# STM32U59x register map
File version: 0.2
Registers are 32-bit, read-write, reset 0x0 unless marked. A register's access mark holds for its fields unless they carry their own. Offsets are from the block's base; [hi:lo] are bit positions; {n}, {i} and the like mark numbered series.

## RCC (part 1 of 2) — Reset and clock control
Base 0x46020C00
Same registers: SEC_RCC 0x56020C00
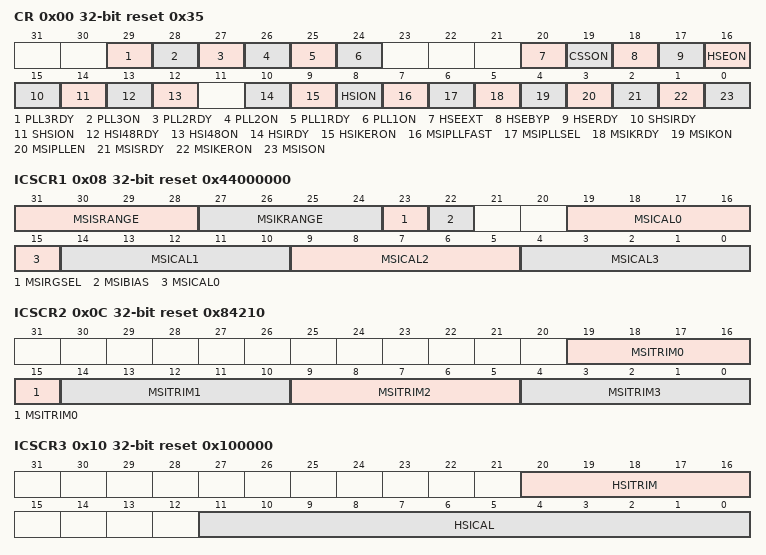
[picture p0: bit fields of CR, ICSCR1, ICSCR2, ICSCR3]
0x00 CR access per field reset 0x35 — Clock control register
  [29] PLL3RDY ro — PLL3 clock ready flag
  [28] PLL3ON rw — PLL3 enable
  [27] PLL2RDY ro — PLL2 clock ready flag
  [26] PLL2ON rw — PLL2 enable
  [25] PLL1RDY ro — PLL1 clock ready flag
  [24] PLL1ON rw — PLL1 enable
  [20] HSEEXT rw — SRAM3 page 5 (64 Kbytes) power-down in Stop modes
  [19] CSSON rw — Clock security system enable
  [18] HSEBYP rw — HSE crystal oscillator bypass
  [17] HSERDY ro — HSE clock ready flag
  [16] HSEON rw — HSE clock enable
  [15] SHSIRDY ro — SHSI clock ready flag
  [14] SHSION rw — SHSI clock enable
  [13] HSI48RDY ro — HSI48 clock ready flag
  [12] HSI48ON rw — HSI48 clock enable
  [10] HSIRDY ro — HSI16 clock ready flag
  [9] HSIKERON rw — HSI16 enable for some peripheral kernels
  [8] HSION rw — HSI16 clock enable
  [7] MSIPLLFAST rw — MSI PLL mode fast startup
  [6] MSIPLLSEL rw — MSI clock with PLL mode selection
  [5] MSIKRDY ro — MSIK clock ready flag
  [4] MSIKON rw — MSIK clock enable
  [3] MSIPLLEN rw — MSI clock PLL-mode enable
  [2] MSISRDY ro — MSIS clock ready flag
  [1] MSIKERON rw — MSI enable for some peripheral kernels
  [0] MSISON rw — MSIS clock enable
0x08 ICSCR1 access per field reset 0x44000000 — Internal clock sources calibration register 1
  [31:28] MSISRANGE rw — MSIS clock ranges
  [27:24] MSIKRANGE rw — MSIK clock ranges
  [23] MSIRGSEL rw — MSI clock range selection
  [22] MSIBIAS rw — MSI bias mode selection
  [19:15] MSICAL0 ro — MSI clock calibration
  [14:10] MSICAL1 ro — MSIRC1 clock calibration
  [9:5] MSICAL2 ro — MSIRC2 clock calibration
  [4:0] MSICAL3 ro — MSIRC3 clock calibration
0x0C ICSCR2 reset 0x84210 — Internal clock sources calibration register 2
  [19:15] MSITRIM0 — MSI clock calibration
  [14:10] MSITRIM1 — MSIRC1 clock calibration
  [9:5] MSITRIM2 — MSIRC2 clock calibration
  [4:0] MSITRIM3 — MSIRC3 clock calibration
0x10 ICSCR3 access per field reset 0x100000 — Internal clock sources calibration register 3
  [20:16] HSITRIM rw — HSI clock trimming
  [11:0] HSICAL ro — HSI clock calibration
0x14 CRRCR ro — clock recovery RC register
  [8:0] HSI48CAL — HSI48 clock calibration
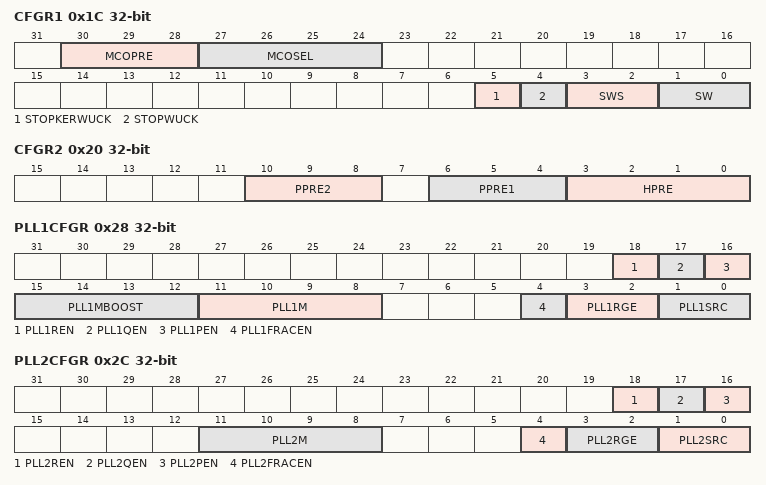
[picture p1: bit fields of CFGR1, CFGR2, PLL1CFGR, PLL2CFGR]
0x1C CFGR1 access per field — clock configuration register 1
  [30:28] MCOPRE rw — microcontroller clock output prescaler
  [27:24] MCOSEL rw — microcontroller clock output
  [5] STOPKERWUCK rw — wakeup from Stop kernel clock automatic enable selection
  [4] STOPWUCK rw — wakeup from Stop and CSS backup clock selection
  [3:2] SWS ro — system clock switch status
  [1:0] SW rw — system clock switch
0x20 CFGR2 — clock configuration register 2
  [10:8] PPRE2 — APB2 prescaler
  [6:4] PPRE1 — APB1 prescaler
  [3:0] HPRE — AHB prescaler
0x24 CFGR3 — clock configuration register 3
  [6:4] PPRE3 — APB3 prescaler
0x28 PLL1CFGR — PLL1 configuration register
  [18] PLL1REN — PLL1 DIVR divider output enable
  [17] PLL1QEN — PLL1 DIVQ divider output enable
  [16] PLL1PEN — PLL1 DIVP divider output enable
  [15:12] PLL1MBOOST — Prescaler for EPOD booster input clock
  [11:8] PLL1M — Prescaler for PLL1
  [4] PLL1FRACEN — PLL1 fractional latch enable
  [3:2] PLL1RGE — PLL1 input frequency range
  [1:0] PLL1SRC — PLL1 entry clock source
0x2C PLL2CFGR — PLL2 configuration register
  [18] PLL2REN — PLL2 DIVR divider output enable
  [17] PLL2QEN — PLL2 DIVQ divider output enable
  [16] PLL2PEN — PLL2 DIVP divider output enable
  [11:8] PLL2M — Prescaler for PLL2
  [4] PLL2FRACEN — PLL2 fractional latch enable
  [3:2] PLL2RGE — PLL2 input frequency range
  [1:0] PLL2SRC — PLL2 entry clock source
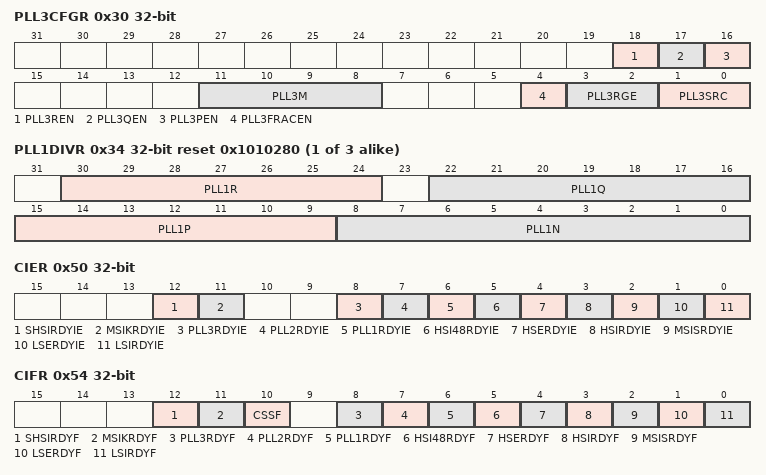
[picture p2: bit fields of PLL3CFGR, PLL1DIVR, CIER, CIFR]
0x30 PLL3CFGR — PLL3 configuration register
  [18] PLL3REN — PLL3 DIVR divider output enable
  [17] PLL3QEN — PLL3 DIVQ divider output enable
  [16] PLL3PEN — PLL3 DIVP divider output enable
  [11:8] PLL3M — Prescaler for PLL3
  [4] PLL3FRACEN — PLL3 fractional latch enable
  [3:2] PLL3RGE — PLL3 input frequency range
  [1:0] PLL3SRC — PLL3 entry clock source
{0x2C+8i} PLL{i}DIVR reset 0x1010280 (i=1..3) — PLL{i} dividers register
  [30:24] PLL{i}R — PLL{i} DIVR division factor
  [22:16] PLL{i}Q — PLL{i} DIVQ division factor
  [15:9] PLL{i}P — PLL{i} DIVP division factor
  [8:0] PLL{i}N — Multiplication factor for PLL{i} VCO
{0x30+8i} PLL{i}FRACR (i=1..3) — PLL{i} fractional divider register
  [15:3] PLL{i}FRACN — Fractional part of the multiplication factor for PLL{i} VCO
0x50 CIER — clock interrupt enable register
  [12] SHSIRDYIE — SHSI ready interrupt enable
  [11] MSIKRDYIE — MSIK ready interrupt enable
  [8] PLL3RDYIE — PLL3 ready interrupt enable
  [7] PLL2RDYIE — PLL2 ready interrupt enable
  [6] PLL1RDYIE — PLL ready interrupt enable
  [5] HSI48RDYIE — HSI48 ready interrupt enable
  [4] HSERDYIE — HSE ready interrupt enable
  [3] HSIRDYIE — HSI16 ready interrupt enable
  [2] MSISRDYIE — MSIS ready interrupt enable
  [1] LSERDYIE — LSE ready interrupt enable
  [0] LSIRDYIE — LSI ready interrupt enable
0x54 CIFR ro — clock interrupt flag register
  [12] SHSIRDYF — SHSI ready interrupt flag
  [11] MSIKRDYF — MSIK ready interrupt flag
  [10] CSSF — Clock security system interrupt flag
  [8] PLL3RDYF — PLL3 ready interrupt flag
  [7] PLL2RDYF — PLL2 ready interrupt flag
  [6] PLL1RDYF — PLL1 ready interrupt flag
  [5] HSI48RDYF — HSI48 ready interrupt flag
  [4] HSERDYF — HSE ready interrupt flag
  [3] HSIRDYF — HSI16 ready interrupt flag
  [2] MSISRDYF — MSIS ready interrupt flag
  [1] LSERDYF — LSE ready interrupt flag
  [0] LSIRDYF — LSI ready interrupt flag
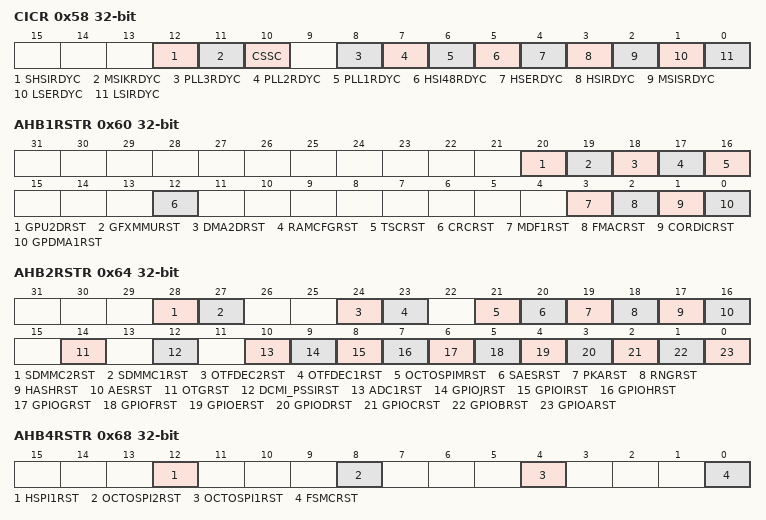
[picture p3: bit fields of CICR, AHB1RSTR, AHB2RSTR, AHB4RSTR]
0x58 CICR wo — clock interrupt clear register
  [12] SHSIRDYC — SHSI ready interrupt clear
  [11] MSIKRDYC — MSIK ready interrupt clear
  [10] CSSC — Clock security system interrupt clear
  [8] PLL3RDYC — PLL3 ready interrupt clear
  [7] PLL2RDYC — PLL2 ready interrupt clear
  [6] PLL1RDYC — PLL1 ready interrupt clear
  [5] HSI48RDYC — HSI48 ready interrupt clear
  [4] HSERDYC — HSE ready interrupt clear
  [3] HSIRDYC — HSI16 ready interrupt clear
  [2] MSISRDYC — MSIS ready interrupt clear
  [1] LSERDYC — LSE ready interrupt clear
  [0] LSIRDYC — LSI ready interrupt clear
0x60 AHB1RSTR — AHB1 peripheral reset register
  [20] GPU2DRST — GPU2D reset Set and cleared by software. Note: This bit is only available in STM32U59x/5Ax. It is reserved in STM32U575/585.
    0=No effect; 1=Reset GPU2D
  [19] GFXMMURST — GFXMMU reset Set and cleared by software. Note: This bit is only available in STM32U59x/5Ax. It is reserved in STM32U575/585.
    0=No effect; 1=Reset GFXMMU
  [18] DMA2DRST — DMA2D reset Set and cleared by software.
    0=No effect; 1=Reset DMA2D
  [17] RAMCFGRST — RAMCFG reset Set and cleared by software.
    0=No effect; 1=Reset RAMCFG
  [16] TSCRST — TSC reset Set and cleared by software.
    0=No effect; 1=Reset TSC
  [12] CRCRST — CRC reset Set and cleared by software.
    0=No effect; 1=Reset CRC
  [3] MDF1RST — MDF1 reset Set and cleared by software.
    0=No effect; 1=Reset MDF1
  [2] FMACRST — FMAC reset Set and cleared by software.
    0=No effect; 1=Reset FMAC
  [1] CORDICRST — CORDIC reset Set and cleared by software.
    0=No effect; 1=Reset CORDIC
  [0] GPDMA1RST — GPDMA1 reset Set and cleared by software.
    0=No effect; 1=Reset GPDMA1
0x64 AHB2RSTR — AHB2 peripheral reset register
  [28] SDMMC2RST — SDMMC2 reset Set and cleared by software.
    0=No effect; 1=Reset SDMMC2
  [27] SDMMC1RST — SDMMC1 reset Set and cleared by software.
    0=No effect; 1=Reset SDMMC1
  [24] OTFDEC2RST — OTFDEC2 reset Set and cleared by software.
    0=No effect; 1=Reset OTFDEC2
  [23] OTFDEC1RST — OTFDEC1 reset Set and cleared by software.
    0=No effect; 1=Reset OTFDEC1
  [21] OCTOSPIMRST — OCTOSPIM reset Set and cleared by software.
    0=No effect; 1=Reset OCTOSPIM
  [20] SAESRST — SAES hardware accelerator reset Set and cleared by software.
    0=No effect; 1=Reset SAES
  [19] PKARST — PKA reset Set and cleared by software.
    0=No effect; 1=Reset PKA
  [18] RNGRST — Random number generator reset Set and cleared by software.
    0=No effect; 1=Reset RNG
  [17] HASHRST — Hash reset Set and cleared by software.
    0=No effect; 1=Reset HASH
  [16] AESRST — AES hardware accelerator reset Set and cleared by software.
    0=No effect; 1=Reset AES
  [14] OTGRST — OTG_FS or OTG_HS reset Set and cleared by software. Note: This bit impacts OTG_FS in STM32U575/585 and in OTG_HS in STM32U59x/5Ax.
    0=No effect; 1=Reset OTG_FS or OTG_HS
  [12] DCMI_PSSIRST — DCMI and PSSI reset Set and cleared by software.
    0=No effect; 1=Reset DCMI and PSSI
  [10] ADC1RST — ADC1 and ADC2 reset Set and cleared by software.
    0=No effect; 1=Reset ADC1 and ADC2
  [9] GPIOJRST — IO port J reset Set and cleared by software. Note: This bit is only available in STM32U59x/5Ax. It is reserved in STM32U575/585.
    0=No effect; 1=Reset IO port J
  [8] GPIOIRST — IO port I reset Set and cleared by software.
    0=No effect; 1=Reset IO port I
  [7] GPIOHRST — IO port H reset Set and cleared by software.
    0=No effect; 1=Reset IO port H
  [6] GPIOGRST — IO port G reset Set and cleared by software.
    0=No effect; 1=Reset IO port G
  [5] GPIOFRST — IO port F reset Set and cleared by software.
    0=No effect; 1=Reset IO port F
  [4] GPIOERST — IO port E reset Set and cleared by software.
    0=No effect; 1=Reset IO port E
  [3] GPIODRST — IO port D reset Set and cleared by software.
    0=No effect; 1=Reset IO port D
  [2] GPIOCRST — IO port C reset Set and cleared by software.
    0=No effect; 1=Reset IO port C
  [1] GPIOBRST — IO port B reset Set and cleared by software.
    0=No effect; 1=Reset IO port B
  [0] GPIOARST — IO port A reset Set and cleared by software.
    0=No effect; 1=Reset IO port A
0x68 AHB4RSTR — AHB4 peripheral reset register
  [12] HSPI1RST — HSPI1 reset Set and cleared by software. Note: This bit is only available in STM32U59x/5Ax. It is reserved in STM32U575/585.
    0=No effect; 1=Reset HSPI1
  [8] OCTOSPI2RST — OCTOSPI2 reset Set and cleared by software.
    0=No effect; 1=Reset OCTOSPI2
  [4] OCTOSPI1RST — OCTOSPI1 reset Set and cleared by software.
    0=No effect; 1=Reset OCTOSPI1
  [0] FSMCRST — Flexible memory controller reset Set and cleared by software.
    0=No effect; 1=Reset FSMC
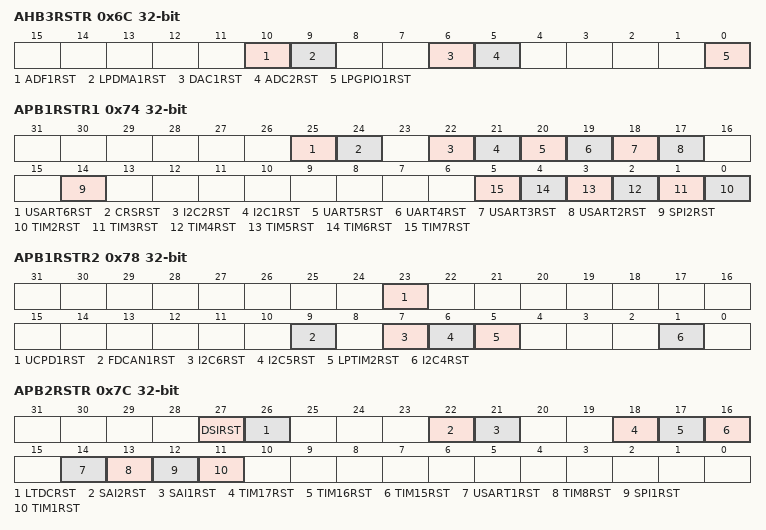
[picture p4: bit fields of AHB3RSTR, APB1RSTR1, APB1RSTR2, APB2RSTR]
0x6C AHB3RSTR — AHB3 peripheral reset register
  [10] ADF1RST — ADF1 reset
  [9] LPDMA1RST — LPDMA1 reset
  [6] DAC1RST — DAC1 reset
  [5] ADC2RST — ADC2 reset
  [0] LPGPIO1RST — LPGPIO1 reset
0x74 APB1RSTR1 — APB1 peripheral reset register 1
  [25] USART6RST — USART6 reset Set and cleared by software. Note: This bit is only available in STM32U59x/5Ax. It is reserved in STM32U575/585.
    0=No effect; 1=Reset the USART6
  [24] CRSRST — CRS reset Set and cleared by software.
    0=No effect; 1=Reset the CRS
  [22] I2C2RST — I2C2 reset Set and cleared by software.
    0=No effect; 1=Reset I2C2
  [21] I2C1RST — I2C1 reset Set and cleared by software.
    0=No effect; 1=Reset I2C1
  [20] UART5RST — UART5 reset Set and cleared by software.
    0=No effect; 1=Reset UART5
  [19] UART4RST — UART4 reset Set and cleared by software.
    0=No effect; 1=Reset UART4
  [18] USART3RST — USART3 reset Set and cleared by software.
    0=No effect; 1=Reset USART3
  [17] USART2RST — USART2 reset Set and cleared by software.
    0=No effect; 1=Reset USART2
  [14] SPI2RST — SPI2 reset Set and cleared by software.
    0=No effect; 1=Reset SPI2
  [n-2] TIM{n}RST (n=2..7) — TIM{n} reset Set and cleared by software.
    0=No effect; 1=Reset TIM{n}
0x78 APB1RSTR2 — APB1 peripheral reset register 2
  [23] UCPD1RST — UCPD1 reset Set and cleared by software.
    0=No effect; 1=Reset UCPD1
  [9] FDCAN1RST — FDCAN1 reset Set and cleared by software.
    0=No effect; 1=Reset FDCAN1
  [7] I2C6RST — I2C6 reset Set and cleared by software Note: This bit is only available in STM32U59x/5Ax. It is reserved in STM32U575/585.
    0=No effect; 1=Reset I2C6
  [6] I2C5RST — I2C5 reset Set and cleared by software Note: This bit is only available in STM32U59x/5Ax. It is reserved in STM32U575/585.
    0=No effect; 1=Reset I2C5
  [5] LPTIM2RST — LPTIM2 reset Set and cleared by software.
    0=No effect; 1=Reset LPTIM2
  [1] I2C4RST — I2C4 reset Set and cleared by software
    0=No effect; 1=Reset I2C4
0x7C APB2RSTR — APB2 peripheral reset register
  [27] DSIRST — DSI reset Set and cleared by software. Note: This bit is only available in STM32U59x/5Ax. It is reserved in STM32U575/585.
    0=No effect; 1=Reset DSI
  [26] LTDCRST — LTDC reset Set and cleared by software. Note: This bit is only available in STM32U59x/5Ax. It is reserved in STM32U575/585.
    0=No effect; 1=Reset LTDC
  [22] SAI2RST — SAI2 reset Set and cleared by software.
    0=No effect; 1=Reset SAI2
  [21] SAI1RST — SAI1 reset Set and cleared by software.
    0=No effect; 1=Reset SAI1
  [18] TIM17RST — TIM17 reset Set and cleared by software.
    0=No effect; 1=Reset TIM17
  [17] TIM16RST — TIM16 reset Set and cleared by software.
    0=No effect; 1=Reset TIM16
  [16] TIM15RST — TIM15 reset Set and cleared by software.
    0=No effect; 1=Reset TIM15
  [14] USART1RST — USART1 reset Set and cleared by software.
    0=No effect; 1=Reset USART1
  [13] TIM8RST — TIM8 reset Set and cleared by software.
    0=No effect; 1=Reset TIM8
  [12] SPI1RST — SPI1 reset Set and cleared by software.
    0=No effect; 1=Reset SPI1
  [11] TIM1RST — TIM1 reset Set and cleared by software.
    0=No effect; 1=Reset TIM1
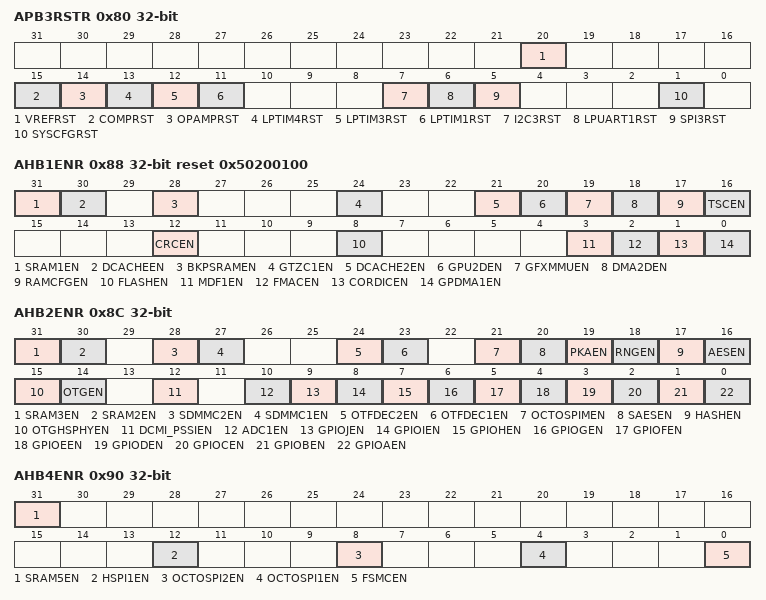
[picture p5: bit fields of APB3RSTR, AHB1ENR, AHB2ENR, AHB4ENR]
0x80 APB3RSTR — APB3 peripheral reset register
  [20] VREFRST — VREFBUF reset
  [15] COMPRST — COMP reset
  [14] OPAMPRST — OPAMP reset
  [13] LPTIM4RST — LPTIM4 reset
  [12] LPTIM3RST — LPTIM3 reset
  [11] LPTIM1RST — LPTIM1 reset
  [7] I2C3RST — I2C3 reset
  [6] LPUART1RST — LPUART1 reset
  [5] SPI3RST — SPI3 reset
  [1] SYSCFGRST — SYSCFG reset
0x88 AHB1ENR reset 0x50200100 — AHB1 peripheral clock enable register
  [31] SRAM1EN
  [30] DCACHEEN — DCACHE clock enable
  [28] BKPSRAMEN — BKPSRAM clock enable
  [24] GTZC1EN — GTZC1 clock enable
  [21] DCACHE2EN
  [20] GPU2DEN
  [19] GFXMMUEN
  [18] DMA2DEN — DMA2D clock enable
  [17] RAMCFGEN — RAMCFG clock enable
  [16] TSCEN — Touch sensing controller clock enable
  [12] CRCEN — CRC clock enable
  [8] FLASHEN — FLASH clock enable
  [3] MDF1EN — MDF1 clock enable
  [2] FMACEN — FMAC clock enable
  [1] CORDICEN — CORDIC clock enable
  [0] GPDMA1EN — GPDMA1 clock enable
0x8C AHB2ENR — AHB2 peripheral clock enable register
  [31] SRAM3EN — SRAM3 clock enable Set and reset by software.
    0=SRAM3 clock disabled; 1=SRAM3 clock enabled
  [30] SRAM2EN — SRAM2 clock enable Set and reset by software.
    0=SRAM2 clock disabled; 1=SRAM2 clock enabled
  [28] SDMMC2EN — SDMMC2 clock enable Set and cleared by software.
    0=SDMMC2 clock disabled; 1=SDMMC2 clock enabled
  [27] SDMMC1EN — SDMMC1 clock enable Set and cleared by software.
    0=SDMMC1 clock disabled; 1=SDMMC1 clock enabled
  [24] OTFDEC2EN — OTFDEC2 clock enable Set and cleared by software.
    0=OTFDEC2 clock disabled; 1=OTFDEC2 clock enabled
  [23] OTFDEC1EN — OTFDEC1 clock enable Set and cleared by software.
    0=OTFDEC1 clock disabled; 1=OTFDEC1 clock enabled
  [21] OCTOSPIMEN — OCTOSPIM clock enable Set and cleared by software.
    0=OCTOSPIM clock disabled; 1=OCTOSPIM clock enabled
  [20] SAESEN — SAES clock enable Set and cleared by software.
    0=SAES clock disabled; 1=SAES clock enabled
  [19] PKAEN — PKA clock enable Set and cleared by software.
    0=PKA clock disabled; 1=PKA clock enabled
  [18] RNGEN — RNG clock enable Set and cleared by software.
    0=RNG clock disabled; 1=RNG clock enabled
  [17] HASHEN — HASH clock enable Set and cleared by software
    0=HASH clock disabled; 1=HASH clock enabled
  [16] AESEN — AES clock enable Set and cleared by software.
    0=AES clock disabled; 1=AES clock enabled
  [15] OTGHSPHYEN — OTG_HS PHY clock enable Set and cleared by software. Note: This bit is only available in STM32U59x/5Ax. It is reserved in STM32U575/585.
    0=OTG_HS PHY clock disabled; 1=OTG_HS PHY clock enabled
  [14] OTGEN — OTG_FS or OTG_HS clock enable Set and cleared by software. Note: This bit impacts OTG_FS in STM32U575/585 and OTG_HS in STM32U59x/5Ax.
    0=OTG_FS or OTG_HS clock disabled; 1=OTG_FS or OTG_HS clock enabled
  [12] DCMI_PSSIEN — DCMI and PSSI clock enable Set and cleared by software.
    0=DCMI and PSSI clock disabled; 1=DCMI and PSSI clock enabled
  [10] ADC1EN — ADC1 and ADC2 clock enable Set and cleared by software. Note: This bit impacts ADC1 in STM32U575/585 and ADC1/ADC2 in STM32U59x/5Ax.
    0=ADC1 and ADC2 clock disabled; 1=ADC1 and ADC2 clock enabled
  [9] GPIOJEN — IO port J clock enable Set and cleared by software. Note: This bit is only available in STM32U59x/5Ax. It is reserved in STM32U575/585.
    0=IO port J clock disabled; 1=IO port J clock enabled
  [8] GPIOIEN — IO port I clock enable Set and cleared by software.
    0=IO port I clock disabled; 1=IO port I clock enabled
  [7] GPIOHEN — IO port H clock enable Set and cleared by software.
    0=IO port H clock disabled; 1=IO port H clock enabled
  [6] GPIOGEN — IO port G clock enable Set and cleared by software.
    0=IO port G clock disabled; 1=IO port G clock enabled
  [5] GPIOFEN — IO port F clock enable Set and cleared by software.
    0=IO port F clock disabled; 1=IO port F clock enabled
  [4] GPIOEEN — IO port E clock enable Set and cleared by software.
    0=IO port E clock disabled; 1=IO port E clock enabled
  [3] GPIODEN — IO port D clock enable Set and cleared by software.
    0=IO port D clock disabled; 1=IO port D clock enabled
  [2] GPIOCEN — IO port C clock enable Set and cleared by software.
    0=IO port C clock disabled; 1=IO port C clock enabled
  [1] GPIOBEN — IO port B clock enable Set and cleared by software.
    0=IO port B clock disabled; 1=IO port B clock enabled
  [0] GPIOAEN — IO port A clock enable Set and cleared by software.
    0=IO port A clock disabled; 1=IO port A clock enabled
0x90 AHB4ENR — AHB4 peripheral clock enable register
  [31] SRAM5EN — SRAM5 clock enable Set and reset by software. Note: This bit is only available in STM32U59x/5Ax. It is reserved in STM32U575/585.
    0=SRAM5 clock disabled; 1=SRAM5 clock enabled
  [12] HSPI1EN — HSPI1 clock enable Set and cleared by software. Note: This bit is only available in STM32U59x/5Ax. It is reserved in STM32U575/585.
    0=HSPI1 clock disabled; 1=HSPI1 clock enabled
  [8] OCTOSPI2EN — OCTOSPI2 clock enable Set and cleared by software.
    0=OCTOSPI2 clock disabled; 1=OCTOSPI2 clock enabled
  [4] OCTOSPI1EN — OCTOSPI1 clock enable Set and cleared by software.
    0=OCTOSPI1 clock disabled; 1=OCTOSPI1 clock enabled
  [0] FSMCEN — FSMC clock enable Set and cleared by software.
    0=FSMC clock disabled; 1=FSMC clock enabled
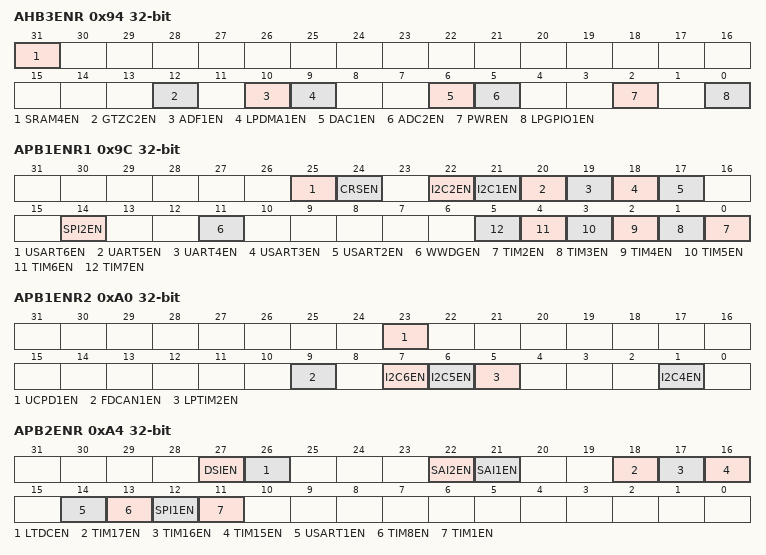
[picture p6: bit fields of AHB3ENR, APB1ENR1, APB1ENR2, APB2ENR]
0x94 AHB3ENR — AHB3 peripheral clock enable register
  [31] SRAM4EN
  [12] GTZC2EN — GTZC2 clock enable
  [10] ADF1EN — ADF1 clock enable
  [9] LPDMA1EN — LPDMA1 clock enable
  [6] DAC1EN — DAC1 clock enable
  [5] ADC2EN — ADC2 clock enable
  [2] PWREN — PWR clock enable
  [0] LPGPIO1EN — LPGPIO1 enable
0x9C APB1ENR1 — APB1 peripheral clock enable register 1
  [25] USART6EN — USART6 clock enable Set and cleared by software. Note: This bit is only available in STM32U59x/5Ax. It is reserved in STM32U575/585.
    0=USART6 clock disabled; 1=USART6 clock enabled
  [24] CRSEN — CRS clock enable Set and cleared by software.
    0=CRS clock disabled; 1=CRS clock enabled
  [22] I2C2EN — I2C2 clock enable Set and cleared by software.
    0=I2C2 clock disabled; 1=I2C2 clock enabled
  [21] I2C1EN — I2C1 clock enable Set and cleared by software.
    0=I2C1 clock disabled; 1=I2C1 clock enabled
  [20] UART5EN — UART5 clock enable Set and cleared by software.
    0=UART5 clock disabled; 1=UART5 clock enabled
  [19] UART4EN — UART4 clock enable Set and cleared by software.
    0=UART4 clock disabled; 1=UART4 clock enabled
  [18] USART3EN — USART3 clock enable Set and cleared by software.
    0=USART3 clock disabled; 1=USART3 clock enabled
  [17] USART2EN — USART2 clock enable Set and cleared by software.
    0=USART2 clock disabled; 1=USART2 clock enabled
  [14] SPI2EN — SPI2 clock enable Set and cleared by software.
    0=SPI2 clock disabled; 1=SPI2 clock enabled
  [11] WWDGEN — WWDG clock enable Set by software to enable the window watchdog clock. Reset by hardware system reset. This bit can also be set by hardware if the WWDG_SW option bit is reset.
    0=WWDG clock disabled; 1=WWDG clock enabled
  [n-2] TIM{n}EN (n=2..7) — TIM{n} clock enable Set and cleared by software.
    0=TIM{n} clock disabled; 1=TIM{n} clock enabled
0xA0 APB1ENR2 — APB1 peripheral clock enable register 2
  [23] UCPD1EN — UCPD1 clock enable Set and cleared by software.
    0=UCPD1 clock disabled; 1=UCPD1 clock enabled
  [9] FDCAN1EN — FDCAN1 clock enable Set and cleared by software.
    0=FDCAN1 clock disabled; 1=FDCAN1 clock enabled
  [7] I2C6EN — I2C6 clock enable Set and cleared by software. Note: This bit is only available in STM32U59x/5Ax. It is reserved in STM32U575/585.
    0=I2C6 clock disabled; 1=I2C6 clock enabled
  [6] I2C5EN — I2C5 clock enable Set and cleared by software. Note: This bit is only available in STM32U59x/5Ax. It is reserved in STM32U575/585.
    0=I2C5 clock disabled; 1=I2C5 clock enabled
  [5] LPTIM2EN — LPTIM2 clock enable Set and cleared by software.
    0=LPTIM2 clock disabled; 1=LPTIM2 clock enabled
  [1] I2C4EN — I2C4 clock enable Set and cleared by software
    0=I2C4 clock disabled; 1=I2C4 clock enabled
0xA4 APB2ENR — APB2 peripheral clock enable register
  [27] DSIEN — DSI clock enable Set and cleared by software. Note: This bit is only available in STM32U59x/5Ax. It is reserved in STM32U575/585.
    0=DSI clock disabled; 1=DSI clock enabled
  [26] LTDCEN — LTDC clock enable Set and cleared by software. Note: This bit is only available in STM32U59x/5Ax. It is reserved in STM32U575/585.
    0=LTDC clock disabled; 1=LTDC clock enabled
  [22] SAI2EN — SAI2 clock enable Set and cleared by software.
    0=SAI2 clock disabled; 1=SAI2 clock enabled
  [21] SAI1EN — SAI1 clock enable Set and cleared by software.
    0=SAI1 clock disabled; 1=SAI1 clock enabled
  [18] TIM17EN — TIM17 clock enable Set and cleared by software.
    0=TIM17 clock disabled; 1=TIM17 clock enabled
  [17] TIM16EN — TIM16 clock enable Set and cleared by software.
    0=TIM16 clock disabled; 1=TIM16 clock enabled
  [16] TIM15EN — TIM15 clock enable Set and cleared by software.
    0=TIM15 clock disabled; 1=TIM15 clock enabled
  [14] USART1EN — USART1clock enable Set and cleared by software.
    0=USART1 clock disabled; 1=USART1 clock enabled
  [13] TIM8EN — TIM8 clock enable Set and cleared by software.
    0=TIM8 clock disabled; 1=TIM8 clock enabled
  [12] SPI1EN — SPI1 clock enable Set and cleared by software.
    0=SPI1 clock disabled; 1=SPI1 clock enabled
  [11] TIM1EN — TIM1 clock enable Set and cleared by software.
    0=TIM1 clock disabled; 1=TIM1 clock enabled
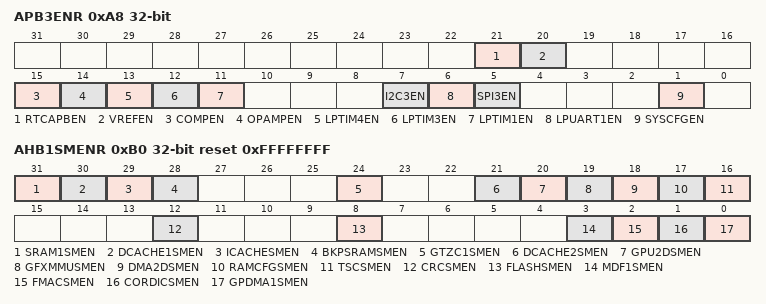
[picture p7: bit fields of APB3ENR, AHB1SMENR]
0xA8 APB3ENR — APB3 peripheral clock enable register
  [21] RTCAPBEN, [20] VREFEN, [15] COMPEN, [14] OPAMPEN, [13] LPTIM4EN, [12] LPTIM3EN, [11] LPTIM1EN, [7] I2C3EN, [6] LPUART1EN, [5] SPI3EN, [1] SYSCFGEN
0xB0 AHB1SMENR reset 0xFFFFFFFF — AHB1 peripheral clocks enable in Sleep and Stop modes register
  [31] SRAM1SMEN — SRAM1 clocks enable during Sleep and Stop modes Set and cleared by software.
    0=SRAM1 clocks disabled by the clock gating during Sleep and Stop modes; 1=SRAM1 clocks enabled by the clock gating during Sleep and Stop modes
  [30] DCACHE1SMEN — DCACHE1 clocks enable during Sleep and Stop modes Set and cleared by software.
    0=DCACHE1 clocks disabled by the clock gating during Sleep and Stop modes; 1=DCACHE1 clocks enabled by the clock gating during Sleep and Stop modes
  [29] ICACHESMEN — ICACHE clocks enable during Sleep and Stop modes Set and cleared by software.
    0=ICACHE clocks disabled by the clock gating during Sleep and Stop modes; 1=ICACHE clocks enabled by the clock gating during Sleep and Stop modes
  [28] BKPSRAMSMEN — BKPSRAM clocks enable during Sleep and Stop modes Set and cleared by software
    0=BKPSRAM clocks disabled by the clock gating during Sleep and Stop modes; 1=BKPSRAM clocks enabled by the clock gating during Sleep and Stop modes
  [24] GTZC1SMEN — GTZC1 clocks enable during Sleep and Stop modes Set and cleared by software.
    0=GTZC1 clocks disabled by the clock gating during Sleep and Stop modes; 1=GTZC1 clocks enabled by the clock gating during Sleep and Stop modes
  [21] DCACHE2SMEN — DCACHE2 clocks enable during Sleep and Stop modes Set and cleared by software. Note: This bit is only available in STM32U59x/5Ax. It is reserved in STM32U575/585.
    0=DCACHE2 clocks disabled by the clock gating during Sleep and Stop modes; 1=DCACHE2 clocks enabled by the clock gating during Sleep and Stop modes
  [20] GPU2DSMEN — GPU2D clocks enable during Sleep and Stop modes Set and cleared by software. Note: This bit is only available in STM32U59x/5Ax. It is reserved in STM32U575/585.
    0=GPU2D clocks disabled by the clock gating during Sleep and Stop modes; 1=GPU2D clocks enabled by the clock gating during Sleep and Stop modes
  [19] GFXMMUSMEN — GFXMMU clocks enable during Sleep and Stop modes Set and cleared by software. Note: This bit is only available in STM32U59x/5Ax. It is reserved in STM32U575/585.
    0=GFXMMU clocks disabled by the clock gating during Sleep and Stop modes; 1=GFXMMU clocks enabled by the clock gating during Sleep and Stop modes
  [18] DMA2DSMEN — DMA2D clocks enable during Sleep and Stop modes Set and cleared by software.
    0=DMA2D clocks disabled by the clock gating during Sleep and Stop modes; 1=DMA2D clocks enabled by the clock gating during Sleep and Stop modes
  [17] RAMCFGSMEN — RAMCFG clocks enable during Sleep and Stop modes Set and cleared by software.
    0=RAMCFG clocks disabled by the clock gating during Sleep and Stop modes; 1=RAMCFG clocks enabled by the clock gating during Sleep and Stop modes
  [16] TSCSMEN — TSC clocks enable during Sleep and Stop modes Set and cleared by software.
    0=TSC clocks disabled by the clock gating during Sleep and Stop modes; 1=TSC clocks enabled by the clock gating during Sleep and Stop modes
  [12] CRCSMEN — CRC clocks enable during Sleep and Stop modes Set and cleared by software.
    0=CRC clocks disabled by the clock gating during Sleep and Stop modes; 1=CRC clocks enabled by the clock gating during Sleep and Stop modes
  [8] FLASHSMEN — FLASH clocks enable during Sleep and Stop modes Set and cleared by software.
    0=FLASH clocks disabled by the clock gating during Sleep and Stop modes; 1=FLASH clocks enabled by the clock gating during Sleep and Stop modes
  [3] MDF1SMEN — MDF1 clocks enable during Sleep and Stop modes. Set and cleared by software. Note: This bit must be set to allow the peripheral to wake up from Stop modes.
    0=MDF1 clocks disabled by the clock gating during Sleep and Stop modes; 1=MDF1 clocks enabled by the clock gating during Sleep and Stop modes
  [2] FMACSMEN — FMAC clocks enable during Sleep and Stop modes. Set and cleared by software.
    0=FMAC clocks disabled by the clock gating during Sleep and Stop modes; 1=FMAC clocks enabled by the clock gating during Sleep and Stop modes
  [1] CORDICSMEN — CORDIC clocks enable during Sleep and Stop modes Set and cleared by software during Sleep mode.
    0=CORDIC clocks disabled by the clock gating during Sleep and Stop modes; 1=CORDIC clocks enabled by the clock gating during Sleep and Stop modes
  [0] GPDMA1SMEN — GPDMA1 clocks enable during Sleep and Stop modes Set and cleared by software. Note: This bit must be set to allow the peripheral to wake up from Stop modes.
    0=GPDMA1 clocks disabled by the clock gating during Sleep and Stop modes; 1=GPDMA1 clocks enabled by the clock gating during Sleep and Stop modes
